# CC3200 register map
Vendor: Texas Instruments; Series: SimpleLink; File version: 1.0
CPU: CM4 r0p1, little endian, MPU, no FPU, 3 interrupt priority bits
Registers are 32-bit, read-write, reset 0x0 unless marked. A register's access mark holds for its fields unless they carry their own. Offsets are from the block's base; [hi:lo] are bit positions; {n}, {i} and the like mark numbered series.

## HIB3P3
Base 0x4402F000
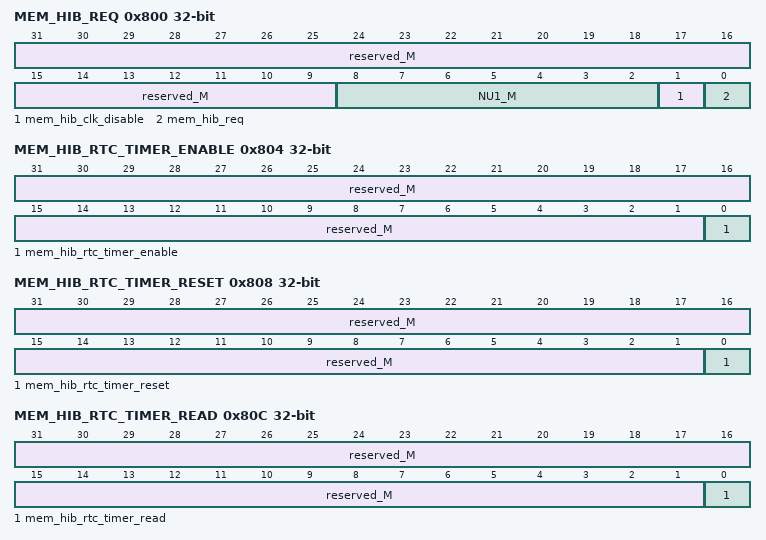
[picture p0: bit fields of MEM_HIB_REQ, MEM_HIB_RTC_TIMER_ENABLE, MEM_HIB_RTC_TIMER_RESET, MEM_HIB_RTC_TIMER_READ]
0x800 MEM_HIB_REQ — HIB3P3_MEM_HIB_REQ
  [31:9] reserved_M — HIB3P3_MEM_HIB_REQ
  [8:2] NU1_M — HIB3P3_MEM_HIB_REQ
  [1] mem_hib_clk_disable — HIB3P3_MEM_HIB_REQ
  [0] mem_hib_req — HIB3P3_MEM_HIB_REQ
0x804 MEM_HIB_RTC_TIMER_ENABLE — HIB3P3_MEM_HIB_RTC_TIMER_ENABLE
  [31:1] reserved_M — HIB3P3_MEM_HIB_RTC_TIMER_ENABLE
  [0] mem_hib_rtc_timer_enable — HIB3P3_MEM_HIB_RTC_TIMER_ENABLE
0x808 MEM_HIB_RTC_TIMER_RESET — HIB3P3_MEM_HIB_RTC_TIMER_RESET
  [31:1] reserved_M — HIB3P3_MEM_HIB_RTC_TIMER_RESET
  [0] mem_hib_rtc_timer_reset — HIB3P3_MEM_HIB_RTC_TIMER_RESET
0x80C MEM_HIB_RTC_TIMER_READ — HIB3P3_MEM_HIB_RTC_TIMER_READ
  [31:1] reserved_M — HIB3P3_MEM_HIB_RTC_TIMER_READ
  [0] mem_hib_rtc_timer_read — HIB3P3_MEM_HIB_RTC_TIMER_READ
0x810 MEM_HIB_RTC_TIMER_LSW — HIB3P3_MEM_HIB_RTC_TIMER_LSW
  [31:0] hib_rtc_timer_lsw_M
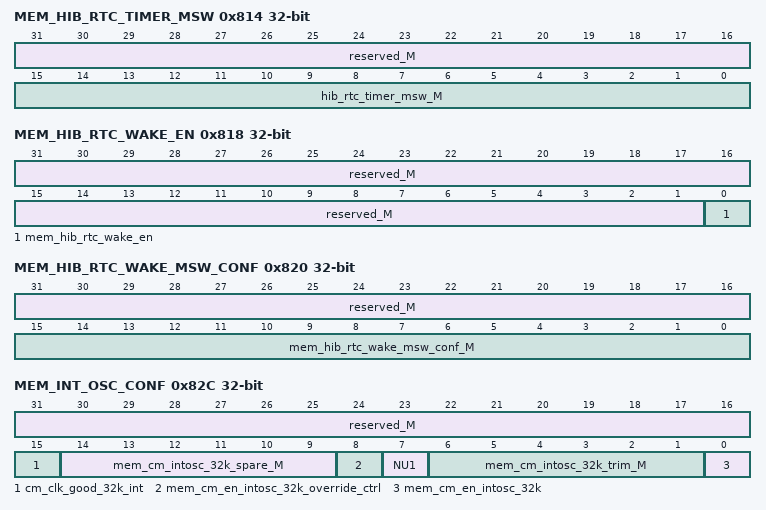
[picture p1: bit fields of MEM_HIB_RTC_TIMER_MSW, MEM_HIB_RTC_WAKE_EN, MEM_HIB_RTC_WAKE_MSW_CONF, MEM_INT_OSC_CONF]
0x814 MEM_HIB_RTC_TIMER_MSW — HIB3P3_MEM_HIB_RTC_TIMER_MSW
  [31:16] reserved_M — HIB3P3_MEM_HIB_RTC_TIMER_MSW
  [15:0] hib_rtc_timer_msw_M — HIB3P3_MEM_HIB_RTC_TIMER_MSW
0x818 MEM_HIB_RTC_WAKE_EN — HIB3P3_MEM_HIB_RTC_WAKE_EN
  [31:1] reserved_M — HIB3P3_MEM_HIB_RTC_WAKE_EN
  [0] mem_hib_rtc_wake_en — HIB3P3_MEM_HIB_RTC_WAKE_EN
0x81C MEM_HIB_RTC_WAKE_LSW_CONF — HIB3P3_MEM_HIB_RTC_WAKE_LSW_CONF
  [31:0] mem_hib_rtc_wake_lsw_conf_M
0x820 MEM_HIB_RTC_WAKE_MSW_CONF — HIB3P3_MEM_HIB_RTC_WAKE_MSW_CONF
  [31:16] reserved_M — HIB3P3_MEM_HIB_RTC_WAKE_MSW_CONF
  [15:0] mem_hib_rtc_wake_msw_conf_M — HIB3P3_MEM_HIB_RTC_WAKE_MSW_CONF
0x82C MEM_INT_OSC_CONF — HIB3P3_MEM_INT_OSC_CONF
  [31:16] reserved_M — HIB3P3_MEM_INT_OSC_CONF
  [15] cm_clk_good_32k_int — HIB3P3_MEM_INT_OSC_CONF
  [14:9] mem_cm_intosc_32k_spare_M — HIB3P3_MEM_INT_OSC_CONF
  [8] mem_cm_en_intosc_32k_override_ctrl — HIB3P3_MEM_INT_OSC_CONF
  [7] NU1 — HIB3P3_MEM_INT_OSC_CONF
  [6:1] mem_cm_intosc_32k_trim_M — HIB3P3_MEM_INT_OSC_CONF
  [0] mem_cm_en_intosc_32k — HIB3P3_MEM_INT_OSC_CONF
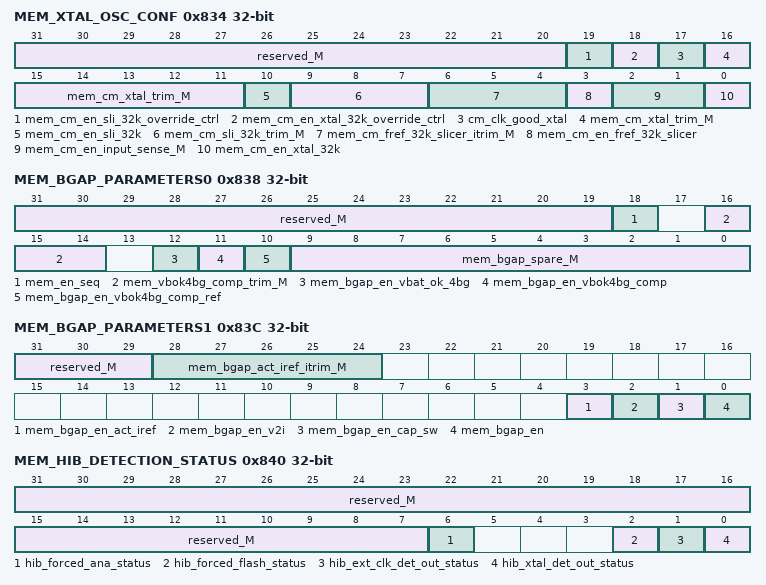
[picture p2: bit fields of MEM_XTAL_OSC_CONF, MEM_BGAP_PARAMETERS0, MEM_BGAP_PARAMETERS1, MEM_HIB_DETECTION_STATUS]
0x834 MEM_XTAL_OSC_CONF — HIB3P3_MEM_XTAL_OSC_CONF
  [31:20] reserved_M — HIB3P3_MEM_XTAL_OSC_CONF
  [19] mem_cm_en_sli_32k_override_ctrl — HIB3P3_MEM_XTAL_OSC_CONF
  [18] mem_cm_en_xtal_32k_override_ctrl — HIB3P3_MEM_XTAL_OSC_CONF
  [17] cm_clk_good_xtal — HIB3P3_MEM_XTAL_OSC_CONF
  [16:11] mem_cm_xtal_trim_M — HIB3P3_MEM_XTAL_OSC_CONF
  [10] mem_cm_en_sli_32k — HIB3P3_MEM_XTAL_OSC_CONF
  [9:7] mem_cm_sli_32k_trim_M — HIB3P3_MEM_XTAL_OSC_CONF
  [6:4] mem_cm_fref_32k_slicer_itrim_M — HIB3P3_MEM_XTAL_OSC_CONF
  [3] mem_cm_en_fref_32k_slicer — HIB3P3_MEM_XTAL_OSC_CONF
  [2:1] mem_cm_en_input_sense_M — HIB3P3_MEM_XTAL_OSC_CONF
  [0] mem_cm_en_xtal_32k — HIB3P3_MEM_XTAL_OSC_CONF
0x838 MEM_BGAP_PARAMETERS0 — HIB3P3_MEM_BGAP_PARAMETERS0
  [31:19] reserved_M — HIB3P3_MEM_BGAP_PARAMETERS0
  [18] mem_en_seq — HIB3P3_MEM_BGAP_PARAMETERS0
  [16:14] mem_vbok4bg_comp_trim_M — HIB3P3_MEM_BGAP_PARAMETERS0
  [12] mem_bgap_en_vbat_ok_4bg — HIB3P3_MEM_BGAP_PARAMETERS0
  [11] mem_bgap_en_vbok4bg_comp — HIB3P3_MEM_BGAP_PARAMETERS0
  [10] mem_bgap_en_vbok4bg_comp_ref — HIB3P3_MEM_BGAP_PARAMETERS0
  [9:0] mem_bgap_spare_M — HIB3P3_MEM_BGAP_PARAMETERS0
0x83C MEM_BGAP_PARAMETERS1 — HIB3P3_MEM_BGAP_PARAMETERS1
  [31:29] reserved_M — HIB3P3_MEM_BGAP_PARAMETERS1
  [28:24] mem_bgap_act_iref_itrim_M — HIB3P3_MEM_BGAP_PARAMETERS1
  [3] mem_bgap_en_act_iref — HIB3P3_MEM_BGAP_PARAMETERS1
  [2] mem_bgap_en_v2i — HIB3P3_MEM_BGAP_PARAMETERS1
  [1] mem_bgap_en_cap_sw — HIB3P3_MEM_BGAP_PARAMETERS1
  [0] mem_bgap_en — HIB3P3_MEM_BGAP_PARAMETERS1
0x840 MEM_HIB_DETECTION_STATUS — HIB3P3_MEM_HIB_DETECTION_STATUS
  [31:7] reserved_M — HIB3P3_MEM_HIB_DETECTION_STATUS
  [6] hib_forced_ana_status — HIB3P3_MEM_HIB_DETECTION_STATUS
  [2] hib_forced_flash_status — HIB3P3_MEM_HIB_DETECTION_STATUS
  [1] hib_ext_clk_det_out_status — HIB3P3_MEM_HIB_DETECTION_STATUS
  [0] hib_xtal_det_out_status — HIB3P3_MEM_HIB_DETECTION_STATUS
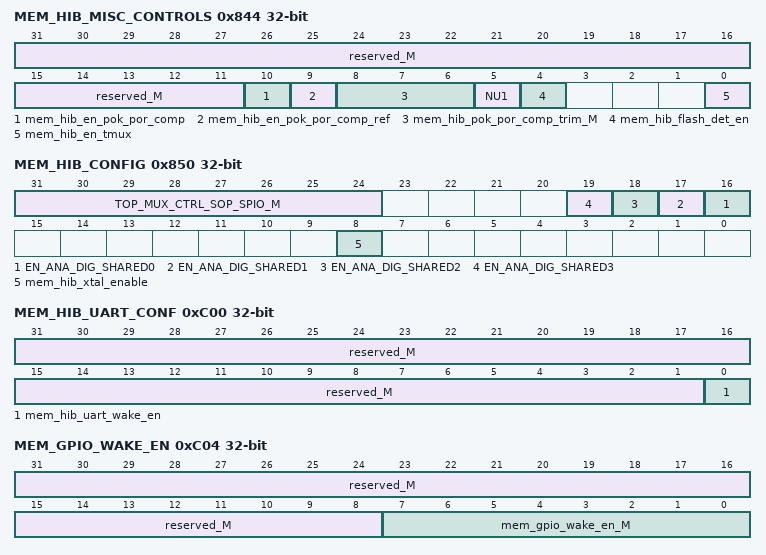
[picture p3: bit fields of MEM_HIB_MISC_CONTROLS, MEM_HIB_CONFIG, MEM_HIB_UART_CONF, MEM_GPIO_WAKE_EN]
0x844 MEM_HIB_MISC_CONTROLS — HIB3P3_MEM_HIB_MISC_CONTROLS
  [31:11] reserved_M — HIB3P3_MEM_HIB_MISC_CONTROLS
  [10] mem_hib_en_pok_por_comp — HIB3P3_MEM_HIB_MISC_CONTROLS
  [9] mem_hib_en_pok_por_comp_ref — HIB3P3_MEM_HIB_MISC_CONTROLS
  [8:6] mem_hib_pok_por_comp_trim_M — HIB3P3_MEM_HIB_MISC_CONTROLS
  [5] NU1 — HIB3P3_MEM_HIB_MISC_CONTROLS
  [4] mem_hib_flash_det_en — HIB3P3_MEM_HIB_MISC_CONTROLS
  [0] mem_hib_en_tmux — HIB3P3_MEM_HIB_MISC_CONTROLS
0x850 MEM_HIB_CONFIG — HIB3P3_MEM_HIB_CONFIG
  [31:24] TOP_MUX_CTRL_SOP_SPIO_M — HIB3P3_MEM_HIB_CONFIG
  [n+16] EN_ANA_DIG_SHARED{n} (n=0..3) — HIB3P3_MEM_HIB_CONFIG
  [8] mem_hib_xtal_enable — HIB3P3_MEM_HIB_CONFIG
0x854 MEM_HIB_RTC_IRQ_ENABLE — HIB3P3_MEM_HIB_RTC_IRQ_ENABLE
  [0] HIB_RTC_IRQ_ENABLE
0x858 MEM_HIB_RTC_IRQ_LSW_CONF — HIB3P3_MEM_HIB_RTC_IRQ_LSW_CONF
  [31:0] HIB_RTC_IRQ_LSW_CONF_M
0x85C MEM_HIB_RTC_IRQ_MSW_CONF — HIB3P3_MEM_HIB_RTC_IRQ_MSW_CONF
  [15:0] HIB_RTC_IRQ_MSW_CONF_M
0xC00 MEM_HIB_UART_CONF — HIB3P3_MEM_HIB_UART_CONF
  [31:1] reserved_M — HIB3P3_MEM_HIB_UART_CONF
  [0] mem_hib_uart_wake_en — HIB3P3_MEM_HIB_UART_CONF
0xC04 MEM_GPIO_WAKE_EN — HIB3P3_MEM_GPIO_WAKE_EN
  [31:8] reserved_M — HIB3P3_MEM_GPIO_WAKE_EN
  [7:0] mem_gpio_wake_en_M — HIB3P3_MEM_GPIO_WAKE_EN
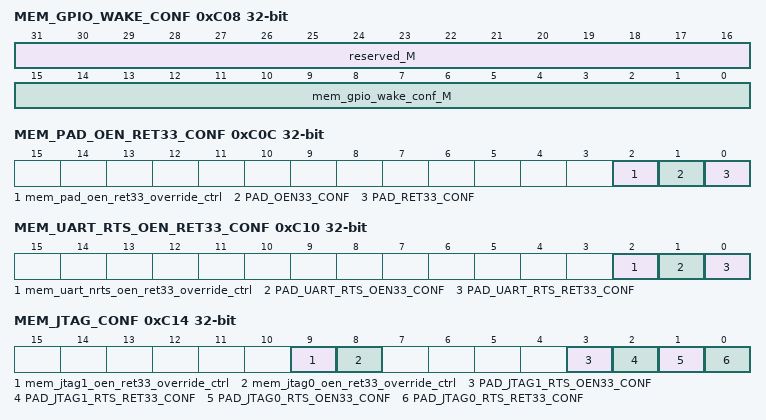
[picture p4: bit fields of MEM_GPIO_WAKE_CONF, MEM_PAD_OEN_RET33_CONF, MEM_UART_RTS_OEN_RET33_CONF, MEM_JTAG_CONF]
0xC08 MEM_GPIO_WAKE_CONF — HIB3P3_MEM_GPIO_WAKE_CONF
  [31:16] reserved_M — HIB3P3_MEM_GPIO_WAKE_CONF
  [15:0] mem_gpio_wake_conf_M — HIB3P3_MEM_GPIO_WAKE_CONF
0xC0C MEM_PAD_OEN_RET33_CONF — HIB3P3_MEM_PAD_OEN_RET33_CONF
  [2] mem_pad_oen_ret33_override_ctrl — HIB3P3_MEM_PAD_OEN_RET33_CONF
  [1] PAD_OEN33_CONF — HIB3P3_MEM_PAD_OEN_RET33_CONF
  [0] PAD_RET33_CONF — HIB3P3_MEM_PAD_OEN_RET33_CONF
0xC10 MEM_UART_RTS_OEN_RET33_CONF — HIB3P3_MEM_UART_RTS_OEN_RET33_CONF
  [2] mem_uart_nrts_oen_ret33_override_ctrl — HIB3P3_MEM_UART_RTS_OEN_RET33_CONF
  [1] PAD_UART_RTS_OEN33_CONF — HIB3P3_MEM_UART_RTS_OEN_RET33_CONF
  [0] PAD_UART_RTS_RET33_CONF — HIB3P3_MEM_UART_RTS_OEN_RET33_CONF
0xC14 MEM_JTAG_CONF — HIB3P3_MEM_JTAG_CONF
  [9] mem_jtag1_oen_ret33_override_ctrl — HIB3P3_MEM_JTAG_CONF
  [8] mem_jtag0_oen_ret33_override_ctrl — HIB3P3_MEM_JTAG_CONF
  [3] PAD_JTAG1_RTS_OEN33_CONF — HIB3P3_MEM_JTAG_CONF
  [2] PAD_JTAG1_RTS_RET33_CONF — HIB3P3_MEM_JTAG_CONF
  [1] PAD_JTAG0_RTS_OEN33_CONF — HIB3P3_MEM_JTAG_CONF
  [0] PAD_JTAG0_RTS_RET33_CONF — HIB3P3_MEM_JTAG_CONF
{0xC18+4i} MEM_HIB_REG{i} (i=0..3) — HIB3P3_MEM_HIB_REG{i}
  [31:0] mem_hib_reg{i}_M
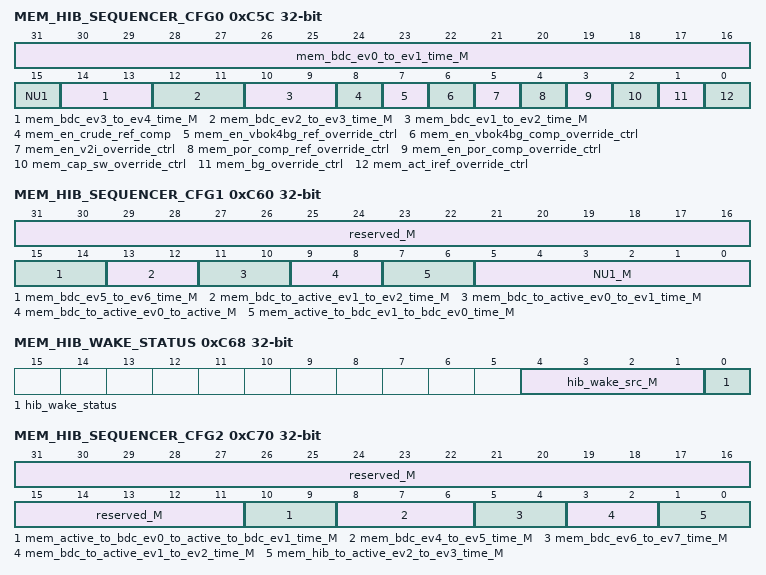
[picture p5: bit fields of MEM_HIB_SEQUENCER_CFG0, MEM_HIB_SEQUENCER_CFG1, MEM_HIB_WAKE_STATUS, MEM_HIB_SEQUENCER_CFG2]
0xC5C MEM_HIB_SEQUENCER_CFG0 — HIB3P3_MEM_HIB_SEQUENCER_CFG0
  [31:16] mem_bdc_ev0_to_ev1_time_M — HIB3P3_MEM_HIB_SEQUENCER_CFG0
  [15] NU1 — HIB3P3_MEM_HIB_SEQUENCER_CFG0
  [14:13] mem_bdc_ev3_to_ev4_time_M — HIB3P3_MEM_HIB_SEQUENCER_CFG0
  [12:11] mem_bdc_ev2_to_ev3_time_M — HIB3P3_MEM_HIB_SEQUENCER_CFG0
  [10:9] mem_bdc_ev1_to_ev2_time_M — HIB3P3_MEM_HIB_SEQUENCER_CFG0
  [8] mem_en_crude_ref_comp — HIB3P3_MEM_HIB_SEQUENCER_CFG0
  [7] mem_en_vbok4bg_ref_override_ctrl — HIB3P3_MEM_HIB_SEQUENCER_CFG0
  [6] mem_en_vbok4bg_comp_override_ctrl — HIB3P3_MEM_HIB_SEQUENCER_CFG0
  [5] mem_en_v2i_override_ctrl — HIB3P3_MEM_HIB_SEQUENCER_CFG0
  [4] mem_por_comp_ref_override_ctrl — HIB3P3_MEM_HIB_SEQUENCER_CFG0
  [3] mem_en_por_comp_override_ctrl — HIB3P3_MEM_HIB_SEQUENCER_CFG0
  [2] mem_cap_sw_override_ctrl — HIB3P3_MEM_HIB_SEQUENCER_CFG0
  [1] mem_bg_override_ctrl — HIB3P3_MEM_HIB_SEQUENCER_CFG0
  [0] mem_act_iref_override_ctrl — HIB3P3_MEM_HIB_SEQUENCER_CFG0
0xC60 MEM_HIB_SEQUENCER_CFG1 — HIB3P3_MEM_HIB_SEQUENCER_CFG1
  [31:16] reserved_M — HIB3P3_MEM_HIB_SEQUENCER_CFG1
  [15:14] mem_bdc_ev5_to_ev6_time_M — HIB3P3_MEM_HIB_SEQUENCER_CFG1
  [13:12] mem_bdc_to_active_ev1_to_ev2_time_M — HIB3P3_MEM_HIB_SEQUENCER_CFG1
  [11:10] mem_bdc_to_active_ev0_to_ev1_time_M — HIB3P3_MEM_HIB_SEQUENCER_CFG1
  [9:8] mem_bdc_to_active_ev0_to_active_M — HIB3P3_MEM_HIB_SEQUENCER_CFG1
  [7:6] mem_active_to_bdc_ev1_to_bdc_ev0_time_M — HIB3P3_MEM_HIB_SEQUENCER_CFG1
  [5:0] NU1_M — HIB3P3_MEM_HIB_SEQUENCER_CFG1
0xC64 MEM_HIB_MISC_CONFIG — HIB3P3_MEM_HIB_MISC_CONFIG
  [0] mem_en_pll_untrim_current
0xC68 MEM_HIB_WAKE_STATUS — HIB3P3_MEM_HIB_WAKE_STATUS
  [4:1] hib_wake_src_M — HIB3P3_MEM_HIB_WAKE_STATUS
  [0] hib_wake_status — HIB3P3_MEM_HIB_WAKE_STATUS
0xC6C MEM_HIB_LPDS_GPIO_SEL — HIB3P3_MEM_HIB_LPDS_GPIO_SEL
  [2:0] HIB_LPDS_GPIO_SEL_M
0xC70 MEM_HIB_SEQUENCER_CFG2 — HIB3P3_MEM_HIB_SEQUENCER_CFG2
  [31:11] reserved_M — HIB3P3_MEM_HIB_SEQUENCER_CFG2
  [10:9] mem_active_to_bdc_ev0_to_active_to_bdc_ev1_time_M — HIB3P3_MEM_HIB_SEQUENCER_CFG2
  [8:6] mem_bdc_ev4_to_ev5_time_M — HIB3P3_MEM_HIB_SEQUENCER_CFG2
  [5:4] mem_bdc_ev6_to_ev7_time_M — HIB3P3_MEM_HIB_SEQUENCER_CFG2
  [3:2] mem_bdc_to_active_ev1_to_ev2_time_M — HIB3P3_MEM_HIB_SEQUENCER_CFG2
  [1:0] mem_hib_to_active_ev2_to_ev3_time_M — HIB3P3_MEM_HIB_SEQUENCER_CFG2
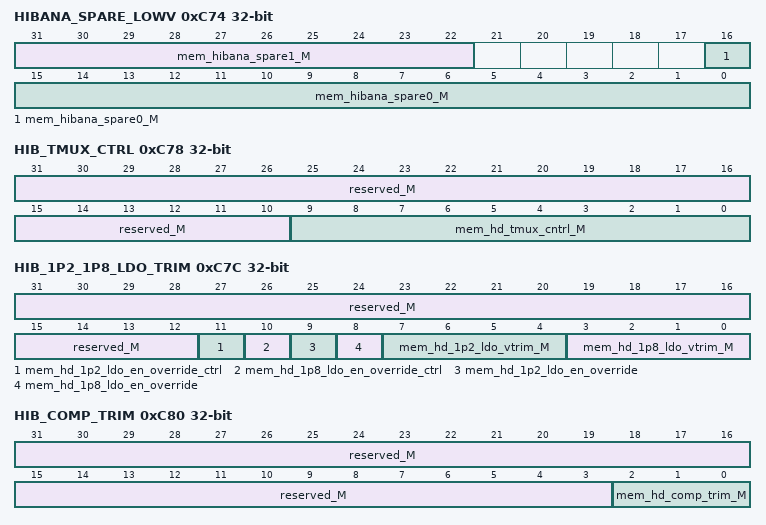
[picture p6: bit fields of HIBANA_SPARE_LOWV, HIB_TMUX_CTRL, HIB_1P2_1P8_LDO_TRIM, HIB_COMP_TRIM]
0xC74 HIBANA_SPARE_LOWV — HIB3P3_HIBANA_SPARE_LOWV
  [31:22] mem_hibana_spare1_M — HIB3P3_HIBANA_SPARE_LOWV
  [16:0] mem_hibana_spare0_M — HIB3P3_HIBANA_SPARE_LOWV
0xC78 HIB_TMUX_CTRL — HIB3P3_HIB_TMUX_CTRL
  [31:10] reserved_M — HIB3P3_HIB_TMUX_CTRL
  [9:0] mem_hd_tmux_cntrl_M — HIB3P3_HIB_TMUX_CTRL
0xC7C HIB_1P2_1P8_LDO_TRIM — HIB3P3_HIB_1P2_1P8_LDO_TRIM
  [31:12] reserved_M — HIB3P3_HIB_1P2_1P8_LDO_TRIM
  [11] mem_hd_1p2_ldo_en_override_ctrl — HIB3P3_HIB_1P2_1P8_LDO_TRIM
  [10] mem_hd_1p8_ldo_en_override_ctrl — HIB3P3_HIB_1P2_1P8_LDO_TRIM
  [9] mem_hd_1p2_ldo_en_override — HIB3P3_HIB_1P2_1P8_LDO_TRIM
  [8] mem_hd_1p8_ldo_en_override — HIB3P3_HIB_1P2_1P8_LDO_TRIM
  [7:4] mem_hd_1p2_ldo_vtrim_M — HIB3P3_HIB_1P2_1P8_LDO_TRIM
  [3:0] mem_hd_1p8_ldo_vtrim_M — HIB3P3_HIB_1P2_1P8_LDO_TRIM
0xC80 HIB_COMP_TRIM — HIB3P3_HIB_COMP_TRIM
  [31:3] reserved_M — HIB3P3_HIB_COMP_TRIM
  [2:0] mem_hd_comp_trim_M — HIB3P3_HIB_COMP_TRIM
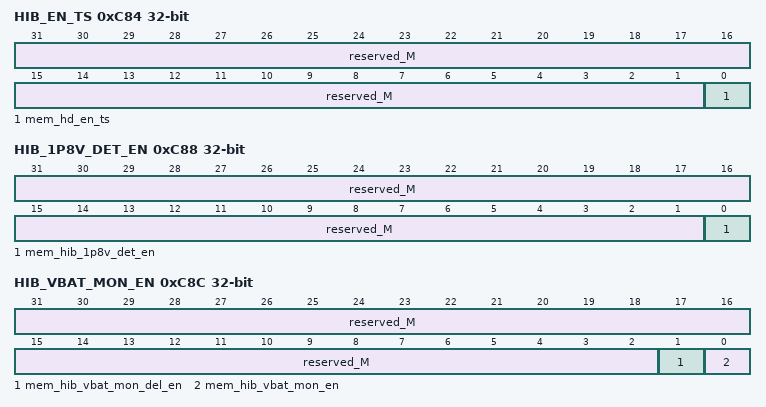
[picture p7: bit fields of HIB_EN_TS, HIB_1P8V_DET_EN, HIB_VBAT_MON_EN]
0xC84 HIB_EN_TS — HIB3P3_HIB_EN_TS
  [31:1] reserved_M — HIB3P3_HIB_EN_TS
  [0] mem_hd_en_ts — HIB3P3_HIB_EN_TS
0xC88 HIB_1P8V_DET_EN — HIB3P3_HIB_1P8V_DET_EN
  [31:1] reserved_M — HIB3P3_HIB_1P8V_DET_EN
  [0] mem_hib_1p8v_det_en — HIB3P3_HIB_1P8V_DET_EN
0xC8C HIB_VBAT_MON_EN — HIB3P3_HIB_VBAT_MON_EN
  [31:2] reserved_M — HIB3P3_HIB_VBAT_MON_EN
  [1] mem_hib_vbat_mon_del_en — HIB3P3_HIB_VBAT_MON_EN
  [0] mem_hib_vbat_mon_en — HIB3P3_HIB_VBAT_MON_EN
0xC90 HIB_NHIB_ENABLE — HIB3P3_HIB_NHIB_ENABLE
  [0] mem_hib_nhib_enable
0xC94 HIB_UART_RTS_SW_ENABLE — HIB3P3_HIB_UART_RTS_SW_ENABLE
  [0] mem_hib_uart_rts_sw_enable
